# M4G7 register map
File version: 0.1
Registers are 32-bit, read-write, reset 0x0 unless marked. A register's access mark holds for its fields unless they carry their own. Offsets are from the block's base; [hi:lo] are bit positions; {n}, {i} and the like mark numbered series; 'fields as' and 'values as' point back to an identical list.

## IA — Interrupt control A Register
Base 0x4003E000
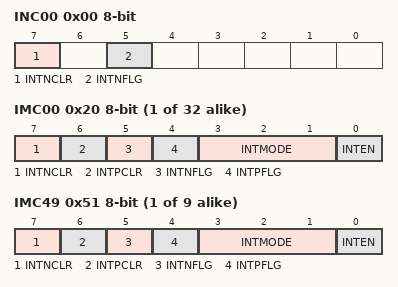
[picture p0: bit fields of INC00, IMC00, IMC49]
0x00 INC00 8-bit — Non Maskable Interrupu Mode Control Register A 00
  [7] INTNCLR wo, [5] INTNFLG ro
{0x20+i} IMC{i:02} 8-bit (i=0..31) — Interrupu Mode Control Register A {i:02}
  [7] INTNCLR wo, [6] INTPCLR wo, [5] INTNFLG ro, [4] INTPFLG ro, [3:1] INTMODE, [0] INTEN
{0x20+i} IMC{i} 8-bit (i=49..57) — Interrupu Mode Control Register A {i}
  fields as IMC00

## RLM — Reset Low power Managiment Register
Base 0x4003E400
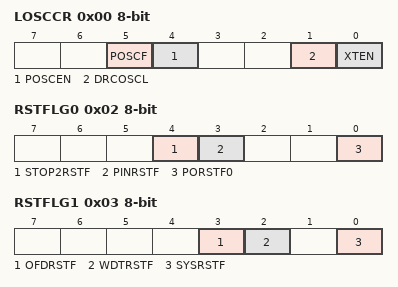
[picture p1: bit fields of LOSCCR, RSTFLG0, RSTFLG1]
0x00 LOSCCR 8-bit — Low OSC and IHOSC2 clock supply Control Register
  [5] POSCF ro, [4] POSCEN, [1] DRCOSCL, [0] XTEN
0x01 SHTDNOP 8-bit — Power Shut Down Control Register
  [0] PTKEEP
0x02 RSTFLG0 8-bit — Reset flag register 0
  [4] STOP2RSTF, [3] PINRSTF, [0] PORSTF0
0x03 RSTFLG1 8-bit — Reset flag register 1
  [3] OFDRSTF, [2] WDTRSTF, [0] SYSRSTF
0x0F PROTECT 8-bit reset 0xC1

## LVD — LVD0
Base 0x4003EC00
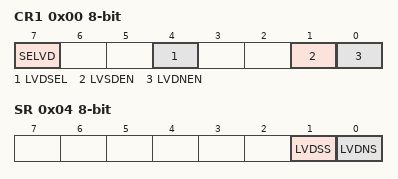
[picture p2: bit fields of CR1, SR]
0x00 CR1 8-bit — LVD Control register1
  [7] SELVD, [4] LVDSEL, [1] LVSDEN, [0] LVDNEN
0x01 CR2 8-bit — LVD Control register2
  [0] LVDOEN
0x02 LVL1 8-bit — LVD detection voltage select register 1
  [3:0] LVDNLVL
0x03 LVL2 8-bit — LVD detection voltage select register 2
  [3:0] LVDSLVL
0x04 SR 8-bit ro (reset mask 0xFC) — LVD status register
  [1] LVDSS, [0] LVDNS

## TSEL — TRGSEL
Base 0x400A0400
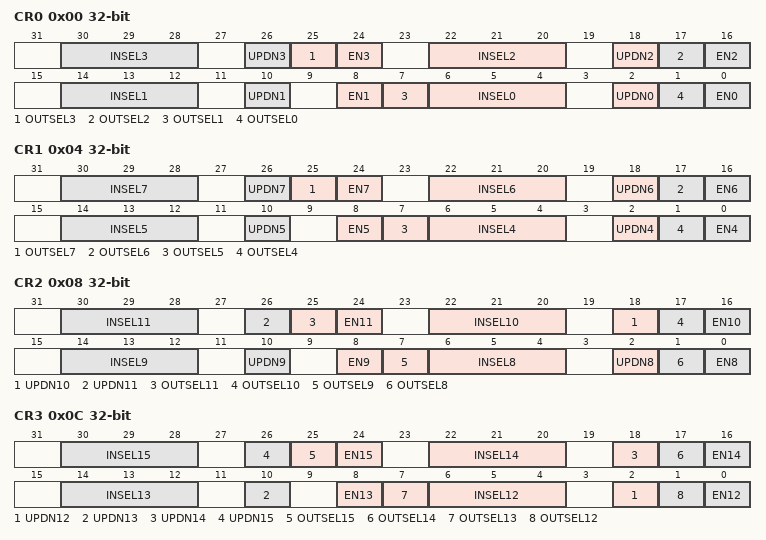
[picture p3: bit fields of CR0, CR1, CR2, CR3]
0x00 CR0 — TRGSEL Control register 0
  [8n+6:8n+4] INSEL{n} (n=0..3), [8n+2] UPDN{n} (n=0..3), [25] OUTSEL3, [8n] EN{n} (n=0..3), [17] OUTSEL2, [7] OUTSEL1, [1] OUTSEL0
0x04 CR1 — TRGSEL Control register 1
  [8n-26:8n-28] INSEL{n} (n=4..7), [8n-30] UPDN{n} (n=4..7), [25] OUTSEL7, [8n-32] EN{n} (n=4..7), [17] OUTSEL6, [7] OUTSEL5, [1] OUTSEL4
0x08 CR2 — TSEL Control register 2
  [8n-58:8n-60] INSEL{n} (n=8..11), [8n-62] UPDN{n} (n=8..11), [25] OUTSEL11, [8n-64] EN{n} (n=8..11), [17] OUTSEL10, [7] OUTSEL9, [1] OUTSEL8
0x0C CR3 — TRGSEL Control register 3
  [8n-90:8n-92] INSEL{n} (n=12..15), [8n-94] UPDN{n} (n=12..15), [25] OUTSEL15, [8n-96] EN{n} (n=12..15), [17] OUTSEL14, [7] OUTSEL13, [1] OUTSEL12
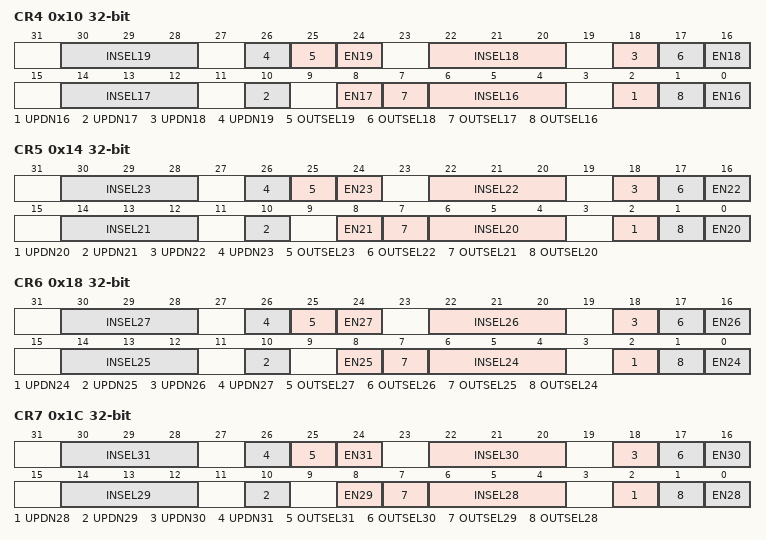
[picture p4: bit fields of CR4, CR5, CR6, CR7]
0x10 CR4 — TRGSEL Control register 4
  [8n-122:8n-124] INSEL{n} (n=16..19), [8n-126] UPDN{n} (n=16..19), [25] OUTSEL19, [8n-128] EN{n} (n=16..19), [17] OUTSEL18, [7] OUTSEL17, [1] OUTSEL16
0x14 CR5 — TRGSEL Control register 5
  [8n-154:8n-156] INSEL{n} (n=20..23), [8n-158] UPDN{n} (n=20..23), [25] OUTSEL23, [8n-160] EN{n} (n=20..23), [17] OUTSEL22, [7] OUTSEL21, [1] OUTSEL20
0x18 CR6 — TRGSEL Control register 6
  [8n-186:8n-188] INSEL{n} (n=24..27), [8n-190] UPDN{n} (n=24..27), [25] OUTSEL27, [8n-192] EN{n} (n=24..27), [17] OUTSEL26, [7] OUTSEL25, [1] OUTSEL24
0x1C CR7 — TRGSEL Control register 7
  [8n-218:8n-220] INSEL{n} (n=28..31), [8n-222] UPDN{n} (n=28..31), [25] OUTSEL31, [8n-224] EN{n} (n=28..31), [17] OUTSEL30, [7] OUTSEL29, [1] OUTSEL28
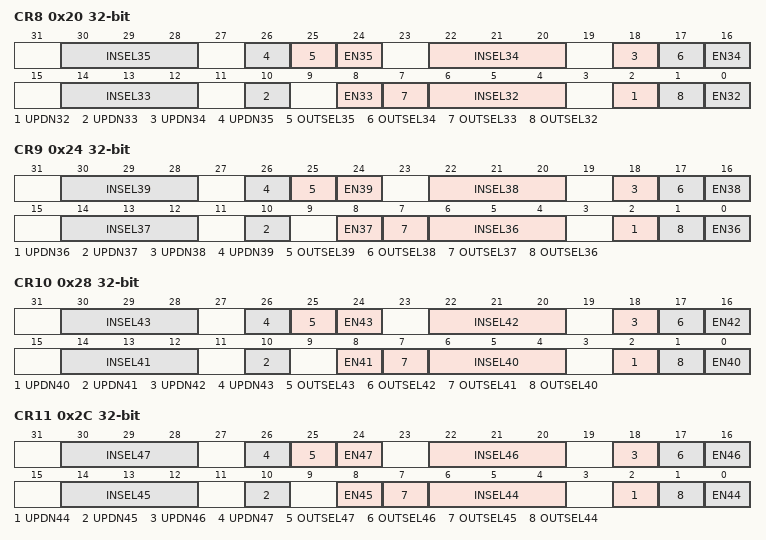
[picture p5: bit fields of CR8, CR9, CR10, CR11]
0x20 CR8 — TRGSEL Control register 8
  [8n-250:8n-252] INSEL{n} (n=32..35), [8n-254] UPDN{n} (n=32..35), [25] OUTSEL35, [8n-256] EN{n} (n=32..35), [17] OUTSEL34, [7] OUTSEL33, [1] OUTSEL32
0x24 CR9 — TRGSEL Control register 9
  [8n-282:8n-284] INSEL{n} (n=36..39), [8n-286] UPDN{n} (n=36..39), [25] OUTSEL39, [8n-288] EN{n} (n=36..39), [17] OUTSEL38, [7] OUTSEL37, [1] OUTSEL36
0x28 CR10 — TRGSEL Control register 10
  [8n-314:8n-316] INSEL{n} (n=40..43), [8n-318] UPDN{n} (n=40..43), [25] OUTSEL43, [8n-320] EN{n} (n=40..43), [17] OUTSEL42, [7] OUTSEL41, [1] OUTSEL40
0x2C CR11 — TRGSEL Control register 11
  [8n-346:8n-348] INSEL{n} (n=44..47), [8n-350] UPDN{n} (n=44..47), [25] OUTSEL47, [8n-352] EN{n} (n=44..47), [17] OUTSEL46, [7] OUTSEL45, [1] OUTSEL44
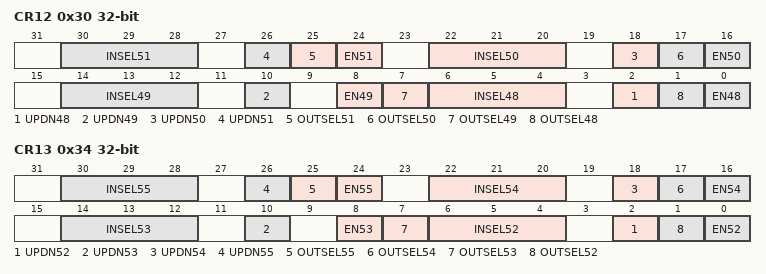
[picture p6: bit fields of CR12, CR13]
0x30 CR12 — TRGSEL Control register 12
  [8n-378:8n-380] INSEL{n} (n=48..51), [8n-382] UPDN{n} (n=48..51), [25] OUTSEL51, [8n-384] EN{n} (n=48..51), [17] OUTSEL50, [7] OUTSEL49, [1] OUTSEL48
0x34 CR13 — TRGSEL Control register 13
  [8n-410:8n-412] INSEL{n} (n=52..55), [8n-414] UPDN{n} (n=52..55), [25] OUTSEL55, [8n-416] EN{n} (n=52..55), [17] OUTSEL54, [7] OUTSEL53, [1] OUTSEL52
